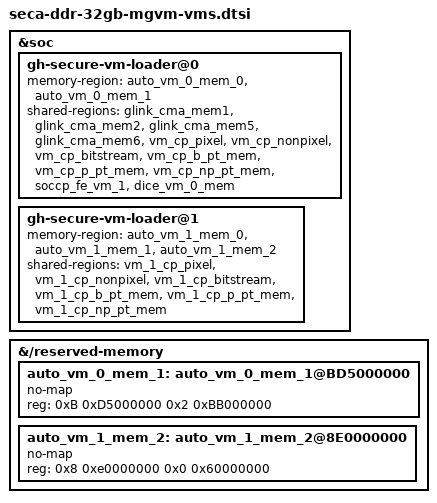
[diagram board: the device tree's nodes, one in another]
// SPDX-License-Identifier: BSD-3-Clause
/*
 * Copyright (c) Qualcomm Technologies, Inc. and/or its subsidiaries.
 */

#include "seca-vms-mgvm.dtsi"

&soc {
	gh-secure-vm-loader@0 {
		memory-region = <&auto_vm_0_mem_0 &auto_vm_0_mem_1>;
		shared-regions = <&glink_cma_mem1
				&glink_cma_mem2
				&glink_cma_mem5
				&glink_cma_mem6
				&vm_cp_pixel
				&vm_cp_nonpixel
				&vm_cp_bitstream
				&vm_cp_b_pt_mem
				&vm_cp_p_pt_mem
				&vm_cp_np_pt_mem
				&soccp_fe_vm_1
				&dice_vm_0_mem>;
	};

	gh-secure-vm-loader@1 {
		memory-region = <&auto_vm_1_mem_0 &auto_vm_1_mem_1 &auto_vm_1_mem_2>;
		shared-regions = <&vm_1_cp_pixel
				&vm_1_cp_nonpixel
				&vm_1_cp_bitstream
				&vm_1_cp_b_pt_mem
				&vm_1_cp_p_pt_mem
				&vm_1_cp_np_pt_mem>;
	};
};

&{/reserved-memory} {

	auto_vm_0_mem_1: auto_vm_0_mem_1@BD5000000 {
		no-map;
		reg = <0xB 0xD5000000 0x2 0xBB000000>; /* 11184MB */
	};

	auto_vm_1_mem_2: auto_vm_1_mem_2@8E0000000 {
		no-map;
		reg = <0x8 0xe0000000 0x0 0x60000000>; /* 2GB */
	};
};
